# MKL82Z7 register map
Vendor: Freescale Semiconductor, Inc.; Series: Kinetis_L; File version: 1.6
CPU: CM0PLUS r0p0, little endian, no MPU, no FPU, VTOR, 2 interrupt priority bits
Registers are 32-bit, read-write, reset 0x0 unless marked. A register's access mark holds for its fields unless they carry their own. Offsets are from the block's base; [hi:lo] are bit positions.

## PMC — Power Management Controller
Base 0x4007D000; register names take the prefix PMC_
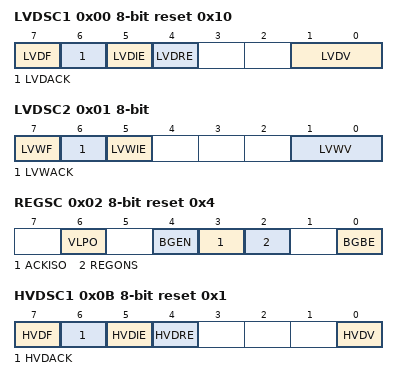
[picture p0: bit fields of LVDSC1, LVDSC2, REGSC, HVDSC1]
0x00 LVDSC1 8-bit reset 0x10 — Low Voltage Detect Status And Control 1 register
  [7] LVDF ro — Low-Voltage Detect Flag
    0=Low-voltage event not detected; 1=Low-voltage event detected
  [6] LVDACK wo — Low-Voltage Detect Acknowledge
  [5] LVDIE — Low-Voltage Detect Interrupt Enable
    0=Hardware interrupt disabled (use polling); 1=Request a hardware interrupt when LVDF = 1
  [4] LVDRE — Low-Voltage Detect Reset Enable
    0=LVDF does not generate hardware resets; 1=Force an MCU reset when LVDF = 1
  [1:0] LVDV — Low-Voltage Detect Voltage Select
    0=Low trip point selected (V LVD = V LVDL ); 1=High trip point selected (V LVD = V LVDH )
0x01 LVDSC2 8-bit — Low Voltage Detect Status And Control 2 register
  [7] LVWF ro — Low-Voltage Warning Flag
    0=Low-voltage warning event not detected; 1=Low-voltage warning event detected
  [6] LVWACK wo — Low-Voltage Warning Acknowledge
  [5] LVWIE — Low-Voltage Warning Interrupt Enable
    0=Hardware interrupt disabled (use polling); 1=Request a hardware interrupt when LVWF = 1
  [1:0] LVWV — Low-Voltage Warning Voltage Select
    0=Low trip point selected (VLVW = VLVW1); 1=Mid 1 trip point selected (VLVW = VLVW2); 2=Mid 2 trip point selected (VLVW = VLVW3); 3=High trip point selected (VLVW = VLVW4)
0x02 REGSC 8-bit reset 0x4 — Regulator Status And Control register
  [6] VLPO — VLPx Option
    0=Operating frequencies and MCG clocking modes are restricted during VLPx modes as listed in the Power Management chapter; 1=If BGEN is also set, operating frequencies and MCG clocking modes are unrestricted during VLPx modes. Note that flash access frequency is still restricted however.
  [4] BGEN — Bandgap Enable In VLPx Operation
    0=Bandgap voltage reference is disabled in VLPx , LLS , and VLLSx modes; 1=Bandgap voltage reference is enabled in VLPx , LLS , and VLLSx modes
  [3] ACKISO — Acknowledge Isolation
    0=Peripherals and I/O pads are in normal run state; 1=Certain peripherals and I/O pads are in an isolated and latched state
  [2] REGONS ro — Regulator In Run Regulation Status
    0=Regulator is in stop regulation or in transition to/from it; 1=Regulator is in run regulation
  [0] BGBE — Bandgap Buffer Enable
    0=Bandgap buffer not enabled; 1=Bandgap buffer enabled
0x0B HVDSC1 8-bit reset 0x1 — High Voltage Detect Status And Control 1 register
  [7] HVDF ro — High-Voltage Detect Flag
    0=High-voltage event not detected; 1=High-voltage event detected
  [6] HVDACK wo — High-Voltage Detect Acknowledge
  [5] HVDIE — High-Voltage Detect Interrupt Enable
    0=Hardware interrupt disabled (use polling); 1=Request a hardware interrupt when HVDF = 1
  [4] HVDRE — High-Voltage Detect Reset Enable
    0=HVDF does not generate hardware resets; 1=Force an MCU reset when HVDF = 1
  [0] HVDV — High-Voltage Detect Voltage Select
    0=Low trip point selected (V HVD = V HVDL ); 1=High trip point selected (V HVD = V HVDH )

## SMC — System Mode Controller
Base 0x4007E000; register names take the prefix SMC_
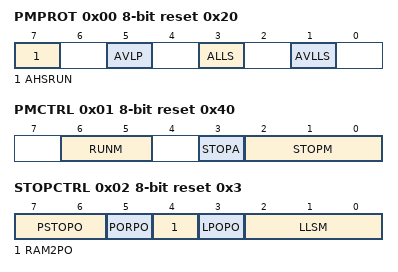
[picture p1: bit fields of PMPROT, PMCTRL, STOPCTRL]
0x00 PMPROT 8-bit reset 0x20 — Power Mode Protection register
  [7] AHSRUN — Allow High Speed Run mode
    0=HSRUN is not allowed; 1=HSRUN is allowed
  [5] AVLP — Allow Very-Low-Power Modes
    0=VLPR, VLPW, and VLPS are not allowed; 1=VLPR, VLPW, and VLPS are allowed
  [3] ALLS — Allow Low-Leakage Stop Mode
    0=Any LLSx mode is not allowed; 1=Any LLSx mode is allowed
  [1] AVLLS — Allow Very-Low-Leakage Stop Mode
    0=Any VLLSx mode is not allowed; 1=Any VLLSx mode is allowed
0x01 PMCTRL 8-bit reset 0x40 — Power Mode Control register
  [6:5] RUNM — Run Mode Control
    0=Normal Run mode (RUN); 2=Very-Low-Power Run mode (VLPR); 3=High Speed Run mode (HSRUN)
  [3] STOPA ro — Stop Aborted
    0=The previous stop mode entry was successsful; 1=The previous stop mode entry was aborted
  [2:0] STOPM — Stop Mode Control
    0=Normal Stop (STOP); 2=Very-Low-Power Stop (VLPS); 3=Low-Leakage Stop (LLSx); 4=Very-Low-Leakage Stop (VLLSx); 6=Reseved
0x02 STOPCTRL 8-bit reset 0x3 — Stop Control Register
  [7:6] PSTOPO — Partial Stop Option
    0=STOP - Normal Stop mode; 1=PSTOP1 - Partial Stop with both system and bus clocks disabled; 2=PSTOP2 - Partial Stop with system clock disabled and bus clock enabled
  [5] PORPO — POR Power Option
    0=POR detect circuit is enabled in VLLS0; 1=POR detect circuit is disabled in VLLS0
  [4] RAM2PO — RAM2 Power Option
    0=RAM2 not powered in LLS2/VLLS2; 1=RAM2 powered in LLS2/VLLS2
  [3] LPOPO — LPO Power Option
    0=LPO clock is enabled in LLS/VLLSx; 1=LPO clock is disabled in LLS/VLLSx
  [2:0] LLSM — LLS or VLLS Mode Control
    0=VLLS0 if PMCTRL[STOPM]=VLLSx, reserved if PMCTRL[STOPM]=LLSx; 1=VLLS1 if PMCTRL[STOPM]=VLLSx, reserved if PMCTRL[STOPM]=LLSx; 2=VLLS2 if PMCTRL[STOPM]=VLLSx, LLS2 if PMCTRL[STOPM]=LLSx; 3=VLLS3 if PMCTRL[STOPM]=VLLSx, LLS3 if PMCTRL[STOPM]=LLSx
0x03 PMSTAT 8-bit ro reset 0x4 — Power Mode Status register
  [7:0] PMSTAT — Power Mode Status

## Notices in the file
Redistribution and use in source and binary forms, with or without modification,
are permitted provided that the following conditions are met:
o Redistributions of source code must retain the above copyright notice, this list
of conditions and the following disclaimer.
o Redistributions in binary form must reproduce the above copyright notice, this
list of conditions and the following disclaimer in the documentation and/or
other materials provided with the distribution.
o Neither the name of Freescale Semiconductor, Inc. nor the names of its
contributors may be used to endorse or promote products derived from this
software without specific prior written permission.
THIS SOFTWARE IS PROVIDED BY THE COPYRIGHT HOLDERS AND CONTRIBUTORS "AS IS" AND
ANY EXPRESS OR IMPLIED WARRANTIES, INCLUDING, BUT NOT LIMITED TO, THE IMPLIED
WARRANTIES OF MERCHANTABILITY AND FITNESS FOR A PARTICULAR PURPOSE ARE
DISCLAIMED. IN NO EVENT SHALL THE COPYRIGHT HOLDER OR CONTRIBUTORS BE LIABLE FOR
ANY DIRECT, INDIRECT, INCIDENTAL, SPECIAL, EXEMPLARY, OR CONSEQUENTIAL DAMAGES
(INCLUDING, BUT NOT LIMITED TO, PROCUREMENT OF SUBSTITUTE GOODS OR SERVICES;
LOSS OF USE, DATA, OR PROFITS; OR BUSINESS INTERRUPTION) HOWEVER CAUSED AND ON
ANY THEORY OF LIABILITY, WHETHER IN CONTRACT, STRICT LIABILITY, OR TORT
(INCLUDING NEGLIGENCE OR OTHERWISE) ARISING IN ANY WAY OUT OF THE USE OF THIS
SOFTWARE, EVEN IF ADVISED OF THE POSSIBILITY OF SUCH DAMAGE.
